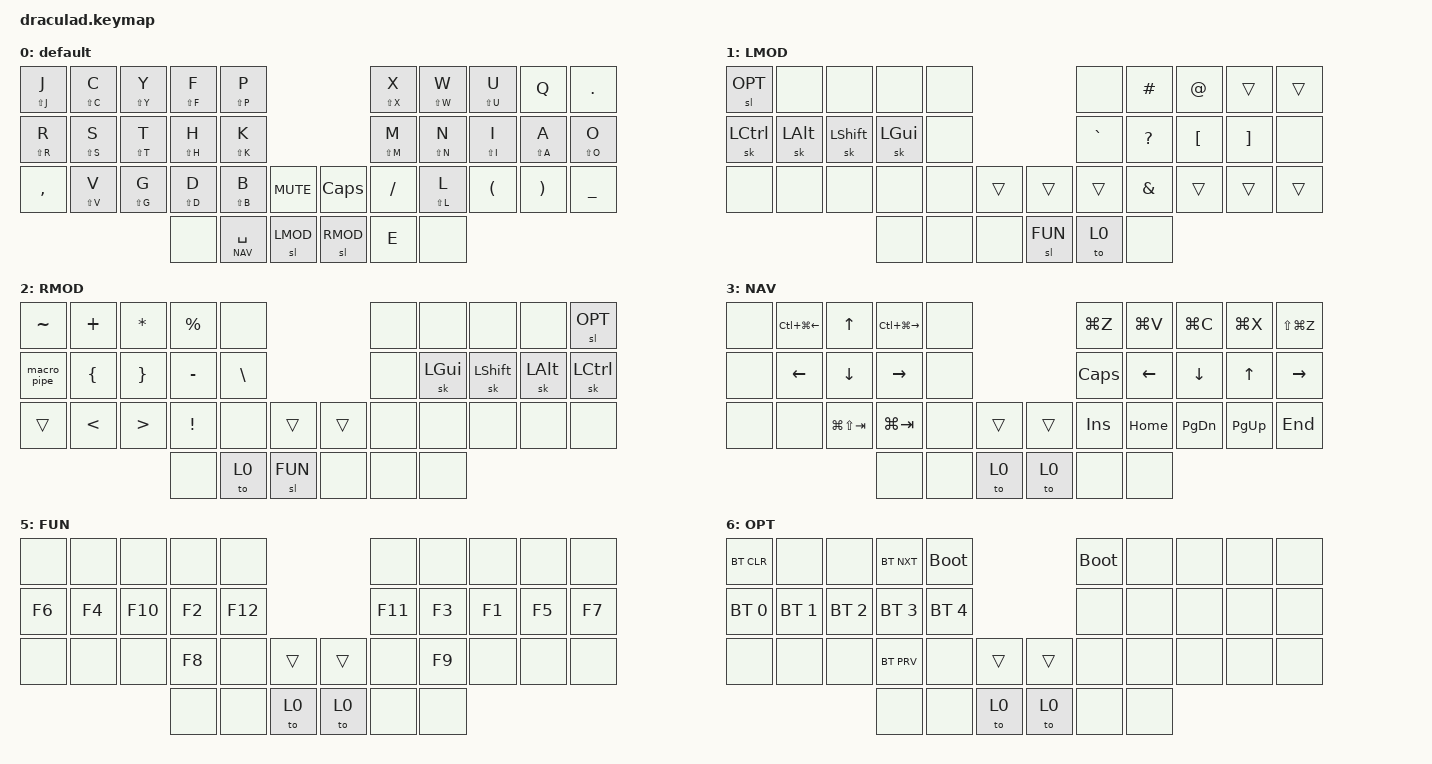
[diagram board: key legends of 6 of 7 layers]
/*
 * Copyright (c) 2020 The ZMK Contributors
 *
 * SPDX-License-Identifier: MIT
 */

#include <behaviors.dtsi>
#include <dt-bindings/zmk/keys.h>
#include <dt-bindings/zmk/bt.h>
#include <dt-bindings/zmk/outputs.h>

// Layers
#define DEFAULT 0
#define LMOD    1
#define RMOD    2
#define NAV     3
#define NUM     4
#define FUN     5
#define OPT     6

// alias
#define BOOT &bootloader

&mt {
    flavor = "tap-preferred";
    tapping-term-ms = <250>;
};

/ {
    combos {
      #include "combos.dtsi"
    };

    behaviors {
      #include "macros.dtsi"
    };

    keymap {
        compatible = "zmk,keymap";

        default {
// --------------------------------------------------------------------------------------------------------------------------------------------------------------------
//  J   |  C   |  Y   |  F   |  P   |             |  X   |  W   |  U   | RPT  |  .   |
//  R   |  S   |  T   |  H   |  K   |             |  M   |  N   |  I   |  A   |  O   |
//  ,   |  V   |  G   |  D   |  B   |             |  /   |  L   |  (   |  )   |  _   |
//                                  | CAPS | MUTE |                                  |
//             |      | LMOD | SPC  |             |  E   | RMOD |      |             |
           bindings = <
            &mt LS(J) J &mt LS(C) C &mt LS(Y) Y &mt LS(F) F &mt LS(P) P                        &mt LS(X) X &mt LS(W) W &mt LS(U) U &kp Q       &kp PERIOD
            &mt LS(R) R &mt LS(S) S &mt LS(T) T &mt LS(H) H &mt LS(K) K                        &mt LS(M) M &mt LS(N) N &mt LS(I) I &mt LS(A) A &mt LS(O) O
            &kp COMMA   &mt LS(V) V &mt LS(G) G &mt LS(D) D &mt LS(B) B   &kp C_MUTE  &kp CAPS &kp SLASH   &mt LS(L) L &kp LPAR    &kp RPAR    &kp UNDER
                                                &none       &lt NAV SPACE &sl LMOD    &sl RMOD &kp E       &none
            >;
            sensor-bindings = <&inc_dec_kp C_VOL_UP C_VOL_DN &inc_dec_kp PG_UP PG_DN>;
        };
        LMOD {
// ------------------------------------------------------------------------.o.o--------------------------------------------------------------------------------------------
// OPT  |      |      |      |      |             |      |  #   |  @   |      |  .   |
// CTRL | ALT  | SHFT | GUI  |      |             |  `   |  ?   |  [   |  ]   |      |
//      |      |      |      |      |             |  /   |  &   |  (   |  )   |  _   |
//                                  | CAPS | MUTE |                                  |
//             |      |      |      |             | DEF  | FUN  |      |             |
           bindings = <
            &sl OPT     &none        &none      &none        &none                              &none      &kp HASH     &kp AT      &trans      &trans
            &sk LCTRL   &sk LALT     &sk LSHFT  &sk LGUI     &none                              &kp GRAVE  &kp QMARK    &kp LBKT    &kp RBKT    &none
            &none       &none        &none      &none        &none       &trans       &trans    &trans     &kp AMPS     &trans      &trans      &trans
                                                &none        &none       &none        &sl FUN   &to 0      &none
           >;
        };
        RMOD {
// --------------------------------------------------------------------------------------------------------------------------------------------------------------------
//  ~   |  +   |  *   |  %   |      |             |      |      |      |      | OPT  |
//  |   |  {   |  }   |  -   |  \   |             |      | GUI  | SHFT | ALT  | CTRL |
//  ,   |  <   |  >   |  !   |      |             |      |      |      |      |      |
//                                  | CAPS | MUTE |                                  |
//             |      | FUN  | DEF  |             |      |      |      |             |
           bindings = <
            &kp TILDE   &kp PLUS     &kp STAR   &kp PRCNT    &none                              &none      &none        &none       &none       &sl OPT
            &macro_pipe &kp LBRC     &kp RBRC   &kp MINUS    &kp BSLH                           &none      &sk LGUI     &sk LSHFT   &sk LALT    &sk LCTRL
            &trans      &kp LT       &kp GT     &kp EXCL     &none       &trans       &trans    &none      &none        &none       &none       &none
                                                &none        &to 0       &sl FUN      &none     &none      &none
           >;

        };
        NAV {
// --------------------------------------------------------------------------------------------------------------------------------------------------------------------
//      | SPC L| UP   | SPC R|      |             | UNDO | PASTE| COPY | CUT  | REDO |
//      | LEFT | DOWN | RIGHT|      |             | CAPS | LEFT | DOWN | UP   | RIGHT|
//      |      | WIN B| WIN L       |             | INS  | HOME | PGDN | PGUP | END  |
//                                  |      |      |                                  |
//             |      |      |      |             |      |      |      |             |
           bindings = <
            &none   &kp LC(LG(LEFT)) &kp UP          &kp LC(LG(RIGHT)) &none                    &kp LG(Z)  &kp LG(V)    &kp LG(C)   &kp LG(X) &kp LS(LG(Z))
            &none   &kp LEFT         &kp DOWN        &kp RIGHT         &none                    &kp CAPS   &kp LEFT     &kp DOWN    &kp UP      &kp RIGHT
            &none   &none            &kp LG(LS(TAB)) &kp LG(TAB)       &none  &trans  &trans    &kp INS    &kp HOME     &kp PG_DN   &kp PG_UP   &kp END
                                                     &none             &none  &to 0   &to 0     &none      &none
           >;
        };
        NUM {
// --------------------------------------------------------------------------------------------------------------------------------------------------------------------
//  J   |  +   |  *   |  %   |      |             |  X   |  -   |      |      |  .   |
//  6   |  4   |  0   |  2   |  K   |             |      |  3   |  1   |  5   |  7   |
//  ,   |      |  G   |  8   |      |             |  /   |  9   |  (   |  )   |  _   |
//                                  |      |      |                                  |
//             |      |      | DEF  |             | DEF  |      |      |             |
           bindings = <
            &kp J       &kp PLUS     &kp STAR   &kp PRCNT    &none                              &trans     &kp MINUS    &none       &none       &trans
            &kp N6      &kp N4       &kp N0     &kp N2       &trans                             &none      &kp N3       &kp N1      &kp N5      &kp N7
            &trans      &none        &kp LS(G)  &kp N8       &none       &trans       &trans    &trans     &kp N9       &trans      &trans      &trans                                                &none        &none       &to 0          &to 0     &none      &none
                                                &none        &none       &to 0        &to 0     &none      &none
            >;
        };
        FUN {
// --------------------------------------------------------------------------------------------------------------------------------------------------------------------
//      |      |      |      |      |             |      |      |      |      |      |
//  F6  |  F4  | F10  |  F2  | F12  |             | F11  |  F3  |  F1  |  F5  |  F7  |
//      |      |      |  F8  |      |             |      |  F9  |      |      |      |
//                                  |      |      |                                  |
//             |      |      |      |             |      |      |      |             |
           bindings = <
            &none       &none        &none      &none        &none                              &none      &none        &none       &none       &none
            &kp F6      &kp F4       &kp F10    &kp F2       &kp F12                            &kp F11    &kp F3       &kp F1      &kp F5      &kp F7
            &none       &none        &none      &kp F8       &none       &trans       &trans    &none      &kp F9       &none       &none       &none
                                                &none        &none       &to 0        &to 0     &none      &none
            >;
        };
        OPT {
// --------------------------------------------------------------------------------------------------------------------------------------------------------------------
//BT_CLR|      |      |BT_NXT| BOOT |             | BOOT |      |      |      |      |
// BT_0 | BT_1 | BT_2 | BT_3 | BT_4 |             |      |      |      |      |      |
//      |      |      |BT_PRV|      |             |      |      |      |      |      |
//                                  |      |      |                                  |
//             |      |      |      |             |      |      |      |             |
// RGB backlighting on right when it ever exists
           bindings = <
            &bt BT_CLR  &none        &none      &bt BT_NXT   BOOT                               BOOT       &none        &none       &none       &none
            &bt BT_SEL 0 &bt BT_SEL 1 &bt BT_SEL 2 &bt BT_SEL 3 &bt BT_SEL 4                    &none      &none        &none       &none       &none
            &none       &none        &none      &bt BT_PRV   &none       &trans       &trans    &none      &none        &none       &none       &none
                                                &none        &none       &to 0        &to 0     &none      &none
            >;
        };
    };
};
